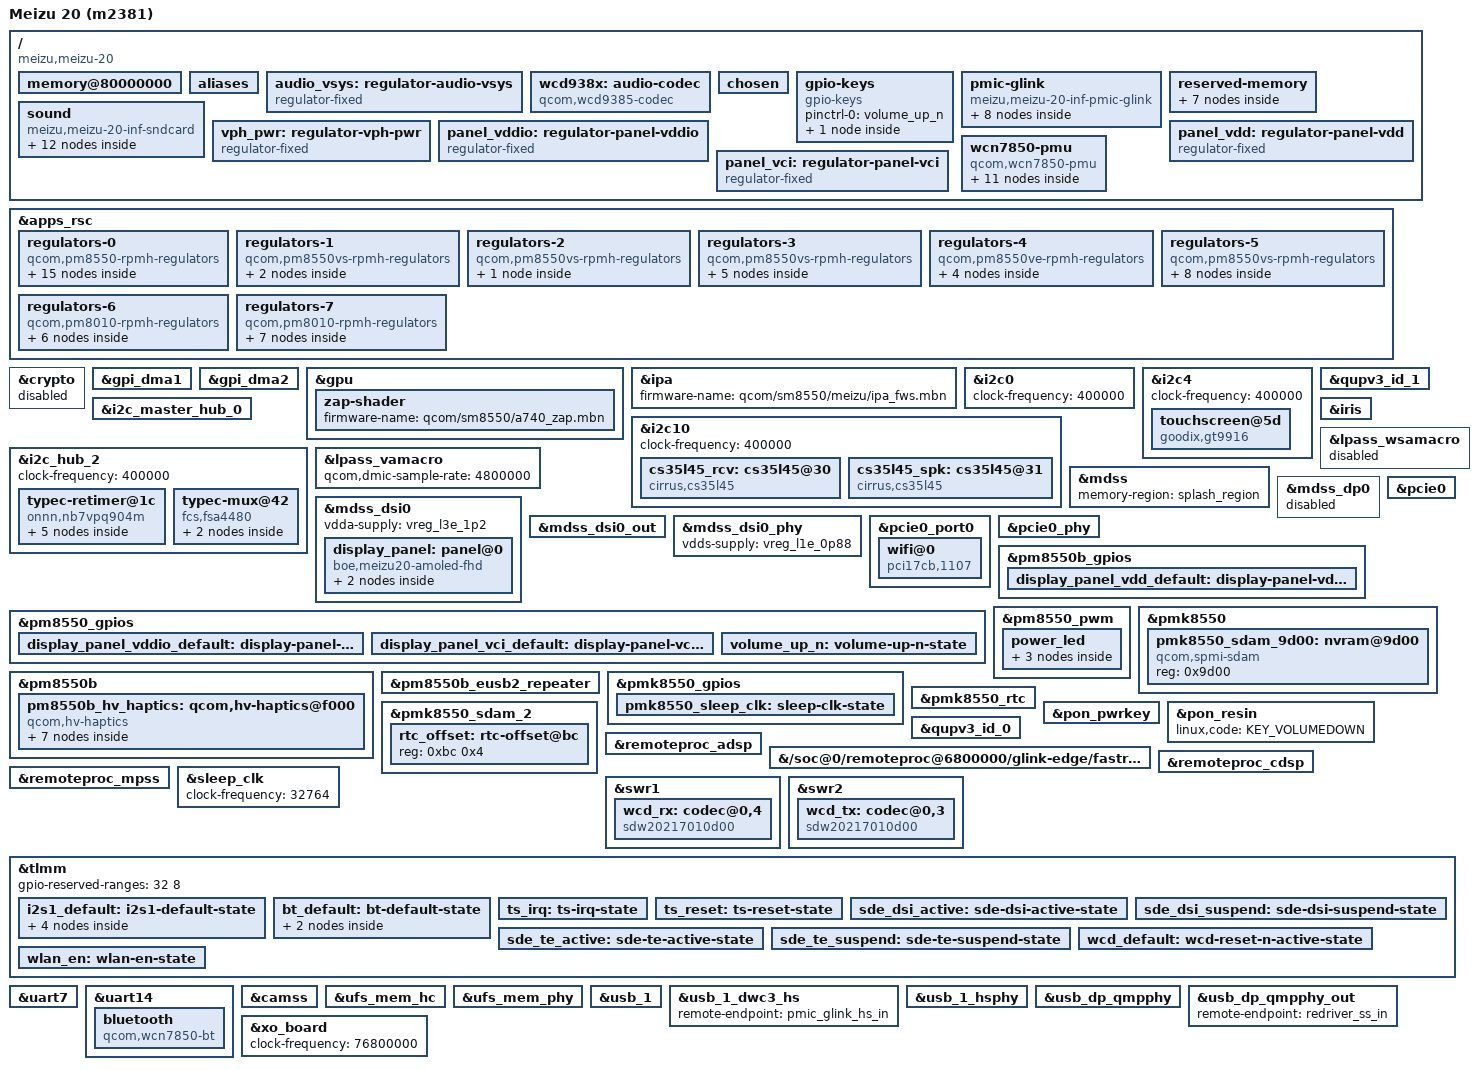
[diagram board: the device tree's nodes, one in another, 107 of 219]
// SPDX-License-Identifier: GPL-2.0-only
/*
 * Device Tree Source for Meizu 20 (m2381, SM8550/Kalama)
 * Copyright (c) 2026 Meizu Technologies
 *
 * factory-first 重建 v2（2026-10-03，DT 原厂化会话②）：
 * 本文件按 2026-10-04 用户拍板方针「本机原厂件为唯一事实源」整文件重建，
 * 取代 inf（Meizu 20 Infinity）派生旧版。逐节点出处与分类 =
 * meizu20-m1/dts/factory-first/LEDGER.md（台账，常驻维护——改此文件必须同步改台账）；
 * 原厂真值 = meizu20-m1/dts/factory-first/corpus/（vendor_boot base DTB + dtbo
 * entry9 + runtime FDT 三源，互验记录见同目录 README 与 reports/）。
 * 出处缩写：entry9 = dtbo entry9（本机生效 overlay）；RT = runtime FDT（ABL 后）。
 */
// SPDX-License-Identifier: BSD-3-Clause
/*
 * Copyright (c) 2025, Teguh Sobirin.
 */

/dts-v1/;
#include <dt-bindings/leds/common.h>
#include <dt-bindings/regulator/qcom,rpmh-regulator.h>
#include <dt-bindings/input/qcom,hv-haptics.h>
#include "sm8550.dtsi"
#include "pm8010.dtsi"
#include "pm8550.dtsi"
#include "pm8550b.dtsi"
#define PMK8550VE_SID 5
#include "pm8550ve.dtsi"
#include "pm8550vs.dtsi"
#include "pmk8550.dtsi"


/delete-node/ &rmtfs_mem;

/* sm8550.dtsi ships a placeholder memory node (reg size 0) and expects "the
 * bootloader to fill in the size".  We boot with a bare arm64 jump, so nobody
 * fills it - and with no /memory at all memblock is empty and paging_init()
 * panics with "Failed to allocate page table page".  The ranges below are
 * copied verbatim from this device's own bootloader-filled tree (stock
 * /sys/firmware/fdt, harvest 2026-09-21 = RT): the stock kernel booted with
 * exactly these values, so they are the platform's authoritative "OS memory".
 */
/delete-node/ &{/memory@a0000000};

/ {
	chassis-type = "handset";

	model = "Meizu 20 (m2381)";
	compatible = "meizu,meizu-20", "qcom,sm8550";

	/* RT: /memory 与本表同源（runtime FDT 即 boot 后地面真值）【D：裸跳需要】 */
	memory@80000000 {
		device_type = "memory";
		reg = <0x00 0x80000000 0x00 0xe00000>,
		      <0x00 0x811d0000 0x00 0x56e30000>,
		      <0x00 0xd8140000 0x00 0x20000>,
		      <0x00 0xd8800000 0x00 0x0>,
		      <0x00 0xe3bb0000 0x00 0x1c450000>,
		      <0x08 0x80000000 0x00 0x38700000>,
		      <0x08 0xc0000000 0x01 0x40000000>,
		      <0x0a 0x00 0x02 0x00>;
	};

	aliases {
		serial0 = &uart7;
		serial1 = &uart14;
	};

	/* CS35L45 VP 供电：stock 为无 GPIO 常开 fixed regulator（代表 VSYS 轨）
	 * 【D：主线 cs35l45 binding 需要 vdd-batt，stock 走不同框架】 */
	audio_vsys: regulator-audio-vsys {
		compatible = "regulator-fixed";
		regulator-name = "audio_vsys";
		regulator-always-on;
		regulator-boot-on;
	};

	wcd938x: audio-codec {
		compatible = "qcom,wcd9385-codec";
		/* reset-gpios=108 与 CS35L45 RCV 的 stock reset 同一网络（见 &i2c10 注），
		 * mainline 由本节点独占持有。
		 * 【A：RT wcd938x_reset_active/sleep = gpio108 ds16】*/
		pinctrl-names = "default";
		pinctrl-0 = <&wcd_default>;

		/* 【B：RT wcd938x-codec qcom,cdc-micbias1..4-mv 全部 0x708=1800mV；
		 * 旧 micbias2=2.7V 为 inf 派生偏差。音频 T3 假设（全 2.75V）与原厂
		 * 相反，随本行作废。2026-10-03 重建。】 */
		qcom,micbias1-microvolt = <1800000>;
		qcom,micbias2-microvolt = <1800000>;
		qcom,micbias3-microvolt = <1800000>;
		qcom,micbias4-microvolt = <1800000>;
		qcom,mbhc-buttons-vthreshold-microvolt = <75000 150000 237000 500000 500000 500000 500000 500000>;
		qcom,mbhc-headset-vthreshold-microvolt = <1700000>;
		qcom,mbhc-headphone-vthreshold-microvolt = <50000>;
		qcom,rx-device = <&wcd_rx>;
		qcom,tx-device = <&wcd_tx>;

		reset-gpios = <&tlmm 108 GPIO_ACTIVE_LOW>;

		vdd-buck-supply = <&vreg_l15b_1p8>;
		vdd-rxtx-supply = <&vreg_l15b_1p8>;
		vdd-io-supply = <&vreg_l15b_1p8>;
		vdd-mic-bias-supply = <&vreg_bob1>;

		#sound-dai-cells = <1>;
	};

	chosen {
		/*
		 * R23bi: no stdout-path on purpose.  The kernel console must become
		 * tty0/fbcon (fed by our glue's sysfb_primary_display fill + the
		 * earlycon=efifb that is already baked into CONFIG_CMDLINE); naming a
		 * serial here would make it the preferred console and the framebuffer
		 * console would stay disabled.
		 * 【D：UEFI 链控制台形态】
		 */
	};

	/* 【A：RT key_vol_up_default = pm8550 gpio6 input-enable pull-up】 */
	gpio-keys {
		compatible = "gpio-keys";

		pinctrl-0 = <&volume_up_n>;
		pinctrl-names = "default";

		key-volume-up {
			label = "Volume Up";
			debounce-interval = <15>;
			gpios = <&pm8550_gpios 6 GPIO_ACTIVE_LOW>;
			linux,code = <KEY_VOLUMEUP>;
			linux,can-disable;
			wakeup-source;
		};
	};

	pmic-glink {
		compatible = "meizu,meizu-20-inf-pmic-glink",
			     "qcom,sm8550-pmic-glink", "qcom,pmic-glink";
		#address-cells = <1>;
		#size-cells = <0>;
		orientation-gpios = <&tlmm 11 GPIO_ACTIVE_HIGH>;

		/*
		 * The board has no wireless charging hardware: the firmware
		 * never answers the wireless supply property requests, so
		 * skip those power supplies entirely.
		 * 【D：功耗战役产物，stock 树无此概念】
		 */
		qcom,no-wireless-charging;

		connector@0 {
			compatible = "usb-c-connector";
			reg = <0>;
			power-role = "dual";
			data-role = "dual";

			ports {
				#address-cells = <1>;
				#size-cells = <0>;

				port@0 {
					reg = <0>;

					pmic_glink_hs_in: endpoint {
						remote-endpoint = <&usb_1_dwc3_hs>;
					};
				};

				port@1 {
					reg = <1>;

					pmic_glink_ss_in: endpoint {
						remote-endpoint = <&redriver_ss_out>;
					};
				};

				port@2 {
					reg = <2>;

					pmic_glink_sbu: endpoint {
						remote-endpoint = <&fsa4480_sbu_mux>;
					};
				};
			};
		};
	};

	reserved-memory {
		/*
		 * Fixed firmware reservations below come from the SoC dtsi
		 * (sm8550.dtsi) plus these board additions, all cross-checked
		 * against the stock m2381 base DTB（2026-09-30 审计；本轮 corpus =
		 * 同一 base，复核入口 = factory-first/corpus/vboot_a.fdt0.dts）:
		 *  - chipinfo@81cf4000: stock-declared, no kernel consumer, kept
		 *    verbatim;
		 *  - hwfence-shbuf: stock is 0x2dd000, SoC dtsi only reserves
		 *    0x279000 - this node intentionally overrides it;
		 *  - llcc_lpi@ff800000: stock-declared, absent from the SoC dtsi;
		 *  - rmtfs@e7900000, splash@b8000000, ramoops@a5100000: board-
		 *    managed carveouts.
		 * 【待捕：全表逐项对账 = 板级分片（台账预留行）；现行值 9-30 审计过】
		 */
		ramoops@a5100000 {
			compatible = "ramoops";
			reg = <0 0xa5100000 0 0x200000>;
			console-size = <0x7d800>;
		};

		chipinfo_mem: chipinfo-region@81cf4000 {
			reg = <0 0x81cf4000 0 0x1000>;
			no-map;
		};

		hwfence_shbuf: hwfence-shbuf-region@e6440000 {
			reg = <0 0xe6440000 0 0x2dd000>;
			no-map;
		};

		llcc_lpi_mem: llcc_lpi_region@ff800000 {
			reg = <0 0xff800000 0 0x600000>;
			no-map;
		};

		rmtfs_mem: rmtfs-region@e7900000 {
			compatible = "qcom,rmtfs-mem";
			reg = <0x0 0xe7900000 0x0 0x280000>;
			no-map;

			qcom,client-id = <1>;
			qcom,vmid = <QCOM_SCM_VMID_MSS_MSA>;
		};

		splash_region: splash-region@b8000000 {
			reg = <0x0 0xb8000000 0x0 0x2b00000>;
			iommu-addresses = <&mdss 0x0 0xb8000000 0x0 0x2b00000>;
			no-map;
		};

		/*
		 * ADSP fastrpc remote heap: stock m2381 declares the same
		 * 12MB reusable pool (adsp_heap_region) and assigns the
		 * static-PD heap to {LPASS 0x16, ADSP_HEAP 0x25} -- same
		 * recipe as upstream sm8250/sm8750/kodiak.
		 */
		adsp_rpc_remote_heap_mem: adsp-rpc-remote-heap {
			compatible = "shared-dma-pool";
			alloc-ranges = <0x0 0x80000000 0x0 0x80000000>;
			reusable;
			alignment = <0x0 0x400000>;
			size = <0x0 0xc00000>;
		};
	};


	sound {
		compatible = "meizu,meizu-20-inf-sndcard",
			     "qcom,sm8550-sndcard", "qcom,sm8450-sndcard";
		pinctrl-0 = <&i2s1_default>;
		pinctrl-names = "default";

		model = "MEIZU20Inf";
		audio-routing = "IN1_HPHL", "HPHL_OUT",
				"IN2_HPHR", "HPHR_OUT",
				"AMIC1", "MIC BIAS1",
				"AMIC2", "MIC BIAS2",
				"AMIC3", "MIC BIAS3",
				"AMIC4", "MIC BIAS3",
				"AMIC5", "MIC BIAS4",
				"TX SWR_INPUT0", "ADC1_OUTPUT",
				"TX SWR_INPUT1", "ADC2_OUTPUT",
				"TX SWR_INPUT0", "ADC3_OUTPUT",
				"TX SWR_INPUT1", "ADC4_OUTPUT";
		wcd-playback-dai-link {
			link-name = "WCD Playback";
			cpu {
				sound-dai = <&q6apmbedai RX_CODEC_DMA_RX_0>;
			};
			codec {
				sound-dai = <&wcd938x 0>, <&swr1 0>, <&lpass_rxmacro 0>;
			};
			platform {
				sound-dai = <&q6apm>;
			};
		};

		wcd-capture-dai-link {
			link-name = "WCD Capture";
			cpu {
				sound-dai = <&q6apmbedai TX_CODEC_DMA_TX_3>;
			};
			codec {
				sound-dai = <&wcd938x 1>, <&swr2 0>, <&lpass_txmacro 0>;
			};
			platform {
				sound-dai = <&q6apm>;
			};
		};

		secondary-i2s-dai-link {
			link-name = "Secondary MI2S Playback";

			cpu {
				sound-dai = <&q6apmbedai SECONDARY_MI2S_RX>;
			};

			platform {
				sound-dai = <&q6apm>;
			};

			codec {
				sound-dai = <&cs35l45_rcv>, <&cs35l45_spk>;
			};
		};

		/*
		 * No displayport-0-dai-link: mdss_dp0 is disabled on m2381
		 * (2026-09-28 panel bring-up, see &mdss_dp0 above). A dai-link
		 * referencing a disabled codec leaves that ASoC component
		 * permanently absent, and the sm8550-sndcard machine driver
		 * silently defers forever = no sound card at all.
		 */
	};

	vph_pwr: regulator-vph-pwr {
		compatible = "regulator-fixed";
		regulator-name = "vph_pwr";
		regulator-min-microvolt = <3700000>;
		regulator-max-microvolt = <3700000>;

		regulator-always-on;
		regulator-boot-on;
	};

	/* ★显示供电三轨（factory-first 重建 2026-10-03，原厂出处见各行）：
	 * stock dsi-display-primary 的 vddio/vdd/vci 全部为 GPIO 门控轨
	 * （display_gpio_regulator@0/1/2，qti-regulator-fixed），不是 RPMH LDO。
	 * 门后物理轨电压由 PMIC 固件决定，节点内电压值 = stock 声明（文档用途）；
	 * r6/r7 活体实测：vddio 1.8V / vdd 1.2V / vci 3.0V——与 stock 声明不完全一致，
	 * 电压值不改物理轨，仅入台账备查。
	 * avdd（stock 供电表 4.6-6.0V，无人引用）：原厂不经 DT 管理该轨（PMIC 上电
	 * 常在），主线驱动 bulk 只取 vddio/vdd/vci ⇒ 不建节点（旧 avdd 5.5V@gpio11
	 * 死配线节点删除——gpio11 的原厂活角色是 vddi 使能）。
	 * 旧 inf 三轨（l12b/l11b/l13b）从 panel 节点摘除；LDO 本体保留在
	 * regulators-0（其他消费者在用）。 */

	/* vddio：RT display_gpio_regulator@0 "display_panel_vddi"，pm8550 gpio11，
	 * 1.8V，boot-on，enable-active-high，ramp 0xe9=233us，
	 * pinctrl display_panel_vddi_default（power-source 1, output-high） */
	panel_vddio: regulator-panel-vddio {
		compatible = "regulator-fixed";
		regulator-name = "display_panel_vddio";
		regulator-min-microvolt = <1800000>;
		regulator-max-microvolt = <1800000>;
		gpio = <&pm8550_gpios 11 GPIO_ACTIVE_HIGH>;
		enable-active-high;
		pinctrl-0 = <&display_panel_vddio_default>;
		pinctrl-names = "default";
		startup-delay-us = <233>;
		regulator-boot-on;
	};

	/* vdd：RT display_gpio_regulator@1 "display_panel_vddr"，pm8550b gpio5，
	 * 1.8V，boot-on，形态同 vddio */
	panel_vdd: regulator-panel-vdd {
		compatible = "regulator-fixed";
		regulator-name = "display_panel_vdd";
		regulator-min-microvolt = <1800000>;
		regulator-max-microvolt = <1800000>;
		gpio = <&pm8550b_gpios 5 GPIO_ACTIVE_HIGH>;
		enable-active-high;
		pinctrl-0 = <&display_panel_vdd_default>;
		pinctrl-names = "default";
		startup-delay-us = <233>;
		regulator-boot-on;
	};

	/* vci：RT display_gpio_regulator@2 "display_panel_vci"，pm8550 gpio1，
	 * 1.8V（声明），boot-on，pinctrl power-source 0（其余两轨为 1） */
	panel_vci: regulator-panel-vci {
		compatible = "regulator-fixed";
		regulator-name = "display_panel_vci";
		regulator-min-microvolt = <1800000>;
		regulator-max-microvolt = <1800000>;
		gpio = <&pm8550_gpios 1 GPIO_ACTIVE_HIGH>;
		enable-active-high;
		pinctrl-0 = <&display_panel_vci_default>;
		pinctrl-names = "default";
		startup-delay-us = <233>;
		regulator-boot-on;
	};

	/* 【A：RT wlan/bt enable pinctrl = gpio80/81；主线 wcn7850-pmu 形态】 */
	wcn7850-pmu {
		compatible = "qcom,wcn7850-pmu";

		pinctrl-names = "default";
		pinctrl-0 = <&wlan_en>, <&bt_default>, <&pmk8550_sleep_clk>;

		wlan-enable-gpios = <&tlmm 80 GPIO_ACTIVE_HIGH>;
        bt-enable-gpios = <&tlmm 81 GPIO_ACTIVE_HIGH>;

		vdd-supply = <&vreg_s5g_0p8>;
		vddio-supply = <&vreg_l15b_1p8>;
		vddaon-supply = <&vreg_s2g_0p8>;
		vdddig-supply = <&vreg_s4e_0p95>;
		vddrfa1p2-supply = <&vreg_s4g_1p3>;
		vddrfa1p8-supply = <&vreg_s6g_1p8>;

		regulators {
			vreg_pmu_rfa_cmn: ldo0 {
				regulator-name = "vreg_pmu_rfa_cmn";
			};

			vreg_pmu_aon_0p59: ldo1 {
				regulator-name = "vreg_pmu_aon_0p59";
			};

			vreg_pmu_wlcx_0p8: ldo2 {
				regulator-name = "vreg_pmu_wlcx_0p8";
			};

			vreg_pmu_wlmx_0p85: ldo3 {
				regulator-name = "vreg_pmu_wlmx_0p85";
			};

			vreg_pmu_btcmx_0p85: ldo4 {
				regulator-name = "vreg_pmu_btcmx_0p85";
			};

			vreg_pmu_rfa_0p8: ldo5 {
				regulator-name = "vreg_pmu_rfa_0p8";
			};

			vreg_pmu_rfa_1p2: ldo6 {
				regulator-name = "vreg_pmu_rfa_1p2";
			};

			vreg_pmu_rfa_1p8: ldo7 {
				regulator-name = "vreg_pmu_rfa_1p8";
			};

			vreg_pmu_pcie_0p9: ldo8 {
				regulator-name = "vreg_pmu_pcie_0p9";
			};

			vreg_pmu_pcie_1p8: ldo9 {
				regulator-name = "vreg_pmu_pcie_1p8";
			};
		};
	};
};

/* RPMH 轨位族：值族沿用 inf 派生（设备现役 20+ 天全子系统实跑验证），
 * **原厂对账 = 未做**（下游 RPMH 轨不在 DT，待板级分片按 RT regulator 节点
 * 逐轨对账，台账标「待捕」）。改轨前先看台账。 */
&apps_rsc {
	regulators-0 {
		compatible = "qcom,pm8550-rpmh-regulators";
		qcom,pmic-id = "b";

		vdd-bob1-supply = <&vph_pwr>;
		vdd-bob2-supply = <&vph_pwr>;
		vdd-l1-l4-l10-supply = <&vreg_s6g_1p8>;
		vdd-l2-l13-l14-supply = <&vreg_bob1>;
		vdd-l3-supply = <&vreg_s4g_1p3>;
		vdd-l5-l16-supply = <&vreg_bob1>;
		vdd-l6-l7-supply = <&vreg_bob1>;
		vdd-l8-l9-supply = <&vreg_bob1>;
		vdd-l11-supply = <&vreg_s4g_1p3>;
		vdd-l12-supply = <&vreg_s6g_1p8>;
		vdd-l15-supply = <&vreg_s6g_1p8>;
		vdd-l17-supply = <&vreg_bob2>;

		vreg_bob1: bob1 {
			regulator-name = "vreg_bob1";
			regulator-min-microvolt = <3296000>;
			regulator-max-microvolt = <3960000>;
			regulator-initial-mode = <RPMH_REGULATOR_MODE_HPM>;
		};

		vreg_bob2: bob2 {
			regulator-name = "vreg_bob2";
			regulator-min-microvolt = <2720000>;
			regulator-max-microvolt = <3960000>;
			regulator-initial-mode = <RPMH_REGULATOR_MODE_HPM>;
		};

		vreg_l2b_3p0: ldo2 {
			regulator-name = "vreg_l2b_3p0";
			regulator-min-microvolt = <3008000>;
			regulator-max-microvolt = <3008000>;
			regulator-initial-mode = <RPMH_REGULATOR_MODE_HPM>;
			regulator-allow-set-load;
			regulator-allowed-modes = <RPMH_REGULATOR_MODE_LPM
					   RPMH_REGULATOR_MODE_HPM>;
		};

		vreg_l5b_3p1: ldo5 {
			regulator-name = "vreg_l5b_3p1";
			regulator-min-microvolt = <3104000>;
			regulator-max-microvolt = <3104000>;
			regulator-initial-mode = <RPMH_REGULATOR_MODE_HPM>;
			regulator-allow-set-load;
			regulator-allowed-modes = <RPMH_REGULATOR_MODE_LPM
					   RPMH_REGULATOR_MODE_HPM>;
		};

		vreg_l6b_1p8: ldo6 {
			regulator-name = "vreg_l6b_1p8";
			regulator-min-microvolt = <1800000>;
			regulator-max-microvolt = <3008000>;
			regulator-initial-mode = <RPMH_REGULATOR_MODE_HPM>;
			regulator-allow-set-load;
			regulator-allowed-modes = <RPMH_REGULATOR_MODE_LPM
					   RPMH_REGULATOR_MODE_HPM>;
		};

		vreg_l7b_1p8: ldo7 {
			regulator-name = "vreg_l7b_1p8";
			regulator-min-microvolt = <1800000>;
			regulator-max-microvolt = <1800000>;
			regulator-initial-mode = <RPMH_REGULATOR_MODE_HPM>;
		};

		vreg_l8b_1p8: ldo8 {
			regulator-name = "vreg_l8b_1p8";
			regulator-min-microvolt = <1800000>;
			regulator-max-microvolt = <3008000>;
			regulator-initial-mode = <RPMH_REGULATOR_MODE_HPM>;
			regulator-allow-set-load;
			regulator-allowed-modes = <RPMH_REGULATOR_MODE_LPM
					   RPMH_REGULATOR_MODE_HPM>;
		};

		vreg_l9b_2p9: ldo9 {
			regulator-name = "vreg_l9b_2p9";
			regulator-min-microvolt = <2960000>;
			regulator-max-microvolt = <3008000>;
			regulator-initial-mode = <RPMH_REGULATOR_MODE_HPM>;
			regulator-allow-set-load;
			regulator-allowed-modes = <RPMH_REGULATOR_MODE_LPM
					   RPMH_REGULATOR_MODE_HPM>;
		};

		vreg_l11b_1p1: ldo11 {
			regulator-name = "vreg_l11b_1p1";
			regulator-min-microvolt = <1100000>;
			regulator-max-microvolt = <1504000>;
			regulator-initial-mode = <RPMH_REGULATOR_MODE_HPM>;
			regulator-allow-set-load;
			regulator-allowed-modes = <RPMH_REGULATOR_MODE_LPM
					   RPMH_REGULATOR_MODE_HPM>;
		};

		vreg_l12b_1p8: ldo12 {
			regulator-name = "vreg_l12b_1p8";
			regulator-min-microvolt = <1800000>;
			regulator-max-microvolt = <1800000>;
			regulator-initial-mode = <RPMH_REGULATOR_MODE_HPM>;
			regulator-allow-set-load;
			regulator-allowed-modes = <RPMH_REGULATOR_MODE_LPM
					   RPMH_REGULATOR_MODE_HPM>;
		};

		vreg_l13b_3p0: ldo13 {
			regulator-name = "vreg_l13b_3p0";
			regulator-min-microvolt = <3000000>;
			regulator-max-microvolt = <3000000>;
			regulator-initial-mode = <RPMH_REGULATOR_MODE_HPM>;
		};

		vreg_l14b_3p2: ldo14 {
			regulator-name = "vreg_l14b_3p2";
			regulator-min-microvolt = <3200000>;
			regulator-max-microvolt = <3200000>;
			regulator-initial-mode = <RPMH_REGULATOR_MODE_HPM>;
		};

		vreg_l15b_1p8: ldo15 {
			regulator-name = "vreg_l15b_1p8";
			regulator-min-microvolt = <1800000>;
			regulator-max-microvolt = <1800000>;
			regulator-initial-mode = <RPMH_REGULATOR_MODE_HPM>;
			regulator-allow-set-load;
			regulator-allowed-modes = <RPMH_REGULATOR_MODE_LPM
					   RPMH_REGULATOR_MODE_HPM>;
		};

		vreg_l16b_2p8: ldo16 {
			regulator-name = "vreg_l16b_2p8";
			regulator-min-microvolt = <2800000>;
			regulator-max-microvolt = <2800000>;
			regulator-initial-mode = <RPMH_REGULATOR_MODE_HPM>;
		};

		vreg_l17b_2p5: ldo17 {
			regulator-name = "vreg_l17b_2p5";
			regulator-min-microvolt = <2504000>;
			regulator-max-microvolt = <2504000>;
			regulator-initial-mode = <RPMH_REGULATOR_MODE_HPM>;
		};
	};

	regulators-1 {
		compatible = "qcom,pm8550vs-rpmh-regulators";
		qcom,pmic-id = "c";

		vdd-l1-supply = <&vreg_s4g_1p3>;
		vdd-l2-supply = <&vreg_s4e_0p95>;
		vdd-l3-supply = <&vreg_s4e_0p95>;

		vreg_l1c_1p2: ldo1 {
			regulator-name = "vreg_l1c_1p2";
			regulator-min-microvolt = <1200000>;
			regulator-max-microvolt = <1200000>;
			regulator-initial-mode = <RPMH_REGULATOR_MODE_HPM>;
			regulator-allow-set-load;
			regulator-allowed-modes = <RPMH_REGULATOR_MODE_LPM
					   RPMH_REGULATOR_MODE_HPM>;
		};

		vreg_l3c_0p9: ldo3 {
			regulator-name = "vreg_l3c_0p9";
			regulator-min-microvolt = <880000>;
			regulator-max-microvolt = <912000>;
			regulator-initial-mode = <RPMH_REGULATOR_MODE_HPM>;
			regulator-allow-set-load;
			regulator-allowed-modes = <RPMH_REGULATOR_MODE_LPM
					   RPMH_REGULATOR_MODE_HPM>;
		};
	};

	regulators-2 {
		compatible = "qcom,pm8550vs-rpmh-regulators";
		qcom,pmic-id = "d";

		vdd-l1-supply = <&vreg_s4e_0p95>;
		vdd-l2-supply = <&vreg_s4e_0p95>;
		vdd-l3-supply = <&vreg_s4e_0p95>;

		vreg_l1d_0p88: ldo1 {
			regulator-name = "vreg_l1d_0p88";
			regulator-min-microvolt = <880000>;
			regulator-max-microvolt = <920000>;
			regulator-initial-mode = <RPMH_REGULATOR_MODE_HPM>;
			regulator-allow-set-load;
			regulator-allowed-modes = <RPMH_REGULATOR_MODE_LPM
					   RPMH_REGULATOR_MODE_HPM>;
		};
	};

	regulators-3 {
		compatible = "qcom,pm8550vs-rpmh-regulators";
		qcom,pmic-id = "e";

		vdd-l1-supply = <&vreg_s4e_0p95>;
		vdd-l2-supply = <&vreg_s4e_0p95>;
		vdd-l3-supply = <&vreg_s4g_1p3>;
		vdd-s4-supply = <&vph_pwr>;
		vdd-s5-supply = <&vph_pwr>;

		vreg_s4e_0p95: smps4 {
			regulator-name = "vreg_s4e_0p95";
			regulator-min-microvolt = <904000>;
			regulator-max-microvolt = <984000>;
			regulator-initial-mode = <RPMH_REGULATOR_MODE_HPM>;
		};

		vreg_s5e_1p08: smps5 {
			regulator-name = "vreg_s5e_1p08";
			regulator-min-microvolt = <1010000>;
			regulator-max-microvolt = <1120000>;
			regulator-initial-mode = <RPMH_REGULATOR_MODE_HPM>;
		};

		vreg_l1e_0p88: ldo1 {
			regulator-name = "vreg_l1e_0p88";
			regulator-min-microvolt = <880000>;
			regulator-max-microvolt = <912000>;
			regulator-initial-mode = <RPMH_REGULATOR_MODE_HPM>;
			regulator-allow-set-load;
			regulator-allowed-modes = <RPMH_REGULATOR_MODE_LPM
					   RPMH_REGULATOR_MODE_HPM>;
		};

		vreg_l2e_0p9: ldo2 {
			regulator-name = "vreg_l2e_0p9";
			regulator-min-microvolt = <870000>;
			regulator-max-microvolt = <970000>;
			regulator-initial-mode = <RPMH_REGULATOR_MODE_HPM>;
			regulator-allow-set-load;
			regulator-allowed-modes = <RPMH_REGULATOR_MODE_LPM
					   RPMH_REGULATOR_MODE_HPM>;
		};

		vreg_l3e_1p2: ldo3 {
			regulator-name = "vreg_l3e_1p2";
			regulator-min-microvolt = <1200000>;
			regulator-max-microvolt = <1200000>;
			regulator-initial-mode = <RPMH_REGULATOR_MODE_HPM>;
		};
	};

	regulators-4 {
		compatible = "qcom,pm8550ve-rpmh-regulators";
		qcom,pmic-id = "f";

		vdd-l1-supply = <&vreg_s4e_0p95>;
		vdd-l2-supply = <&vreg_s4e_0p95>;
		vdd-l3-supply = <&vreg_s4e_0p95>;
		vdd-s4-supply = <&vph_pwr>;

		vreg_s4f_0p5: smps4 {
			regulator-name = "vreg_s4f_0p5";
			regulator-min-microvolt = <300000>;
			regulator-max-microvolt = <700000>;
			regulator-initial-mode = <RPMH_REGULATOR_MODE_HPM>;
		};

		vreg_l1f_0p9: ldo1 {
			regulator-name = "vreg_l1f_0p9";
			regulator-min-microvolt = <880000>;
			regulator-max-microvolt = <912000>;
			regulator-initial-mode = <RPMH_REGULATOR_MODE_HPM>;
			regulator-allow-set-load;
			regulator-allowed-modes = <RPMH_REGULATOR_MODE_LPM
					   RPMH_REGULATOR_MODE_HPM>;
		};

		vreg_l2f_0p88: ldo2 {
			regulator-name = "vreg_l2f_0p88";
			regulator-min-microvolt = <880000>;
			regulator-max-microvolt = <912000>;
			regulator-initial-mode = <RPMH_REGULATOR_MODE_HPM>;
			regulator-allow-set-load;
			regulator-allowed-modes = <RPMH_REGULATOR_MODE_LPM
					   RPMH_REGULATOR_MODE_HPM>;
		};

		vreg_l3f_0p88: ldo3 {
			regulator-name = "vreg_l3f_0p88";
			regulator-min-microvolt = <880000>;
			regulator-max-microvolt = <912000>;
			regulator-initial-mode = <RPMH_REGULATOR_MODE_HPM>;
			regulator-allow-set-load;
			regulator-allowed-modes = <RPMH_REGULATOR_MODE_LPM
					   RPMH_REGULATOR_MODE_HPM>;
		};
	};

	regulators-5 {
		compatible = "qcom,pm8550vs-rpmh-regulators";
		qcom,pmic-id = "g";

		vdd-l1-supply = <&vreg_s4g_1p3>;
		vdd-l2-supply = <&vreg_s4g_1p3>;
		vdd-l3-supply = <&vreg_s4g_1p3>;
		vdd-s1-supply = <&vph_pwr>;
		vdd-s2-supply = <&vph_pwr>;
		vdd-s3-supply = <&vph_pwr>;
		vdd-s4-supply = <&vph_pwr>;
		vdd-s5-supply = <&vph_pwr>;
		vdd-s6-supply = <&vph_pwr>;

		vreg_s1g_1p2: smps1 {
			regulator-name = "vreg_s1g_1p2";
			regulator-min-microvolt = <1200000>;
			regulator-max-microvolt = <1300000>;
			regulator-initial-mode = <RPMH_REGULATOR_MODE_HPM>;
		};

		vreg_s2g_0p8: smps2 {
			regulator-name = "vreg_s2g_0p8";
			regulator-min-microvolt = <500000>;
			regulator-max-microvolt = <1036000>;
			regulator-initial-mode = <RPMH_REGULATOR_MODE_HPM>;
		};

		vreg_s3g_0p7: smps3 {
			regulator-name = "vreg_s3g_0p7";
			regulator-min-microvolt = <300000>;
			regulator-max-microvolt = <1004000>;
			regulator-initial-mode = <RPMH_REGULATOR_MODE_HPM>;
		};

		vreg_s4g_1p3: smps4 {
			regulator-name = "vreg_s4g_1p3";
			regulator-min-microvolt = <1200000>;
			regulator-max-microvolt = <1352000>;
			regulator-initial-mode = <RPMH_REGULATOR_MODE_HPM>;
		};

		vreg_s5g_0p8: smps5 {
			regulator-name = "vreg_s5g_0p8";
			regulator-min-microvolt = <500000>;
			regulator-max-microvolt = <1004000>;
			regulator-initial-mode = <RPMH_REGULATOR_MODE_HPM>;
		};

		vreg_s6g_1p8: smps6 {
			regulator-name = "vreg_s6g_1p8";
			regulator-min-microvolt = <1800000>;
			regulator-max-microvolt = <2000000>;
			regulator-initial-mode = <RPMH_REGULATOR_MODE_HPM>;
		};

		vreg_l1g_1p2: ldo1 {
			regulator-name = "vreg_l1g_1p2";
			regulator-min-microvolt = <1200000>;
			regulator-max-microvolt = <1200000>;
			regulator-initial-mode = <RPMH_REGULATOR_MODE_HPM>;
			regulator-allow-set-load;
			regulator-allowed-modes = <RPMH_REGULATOR_MODE_LPM
					   RPMH_REGULATOR_MODE_HPM>;
		};

		vreg_l3g_1p2: ldo3 {
			regulator-name = "vreg_l3g_1p2";
			regulator-min-microvolt = <1200000>;
			regulator-max-microvolt = <1200000>;
			regulator-initial-mode = <RPMH_REGULATOR_MODE_HPM>;
		};
	};

	regulators-6 {
		compatible = "qcom,pm8010-rpmh-regulators";
		qcom,pmic-id = "m";

		vdd-l1-l2-supply = <&vreg_s4g_1p3>;
		vdd-l3-l4-supply = <&vreg_bob2>;
		vdd-l5-supply = <&vreg_s6g_1p8>;
		vdd-l6-supply = <&vreg_bob2>;
		vdd-l7-supply = <&vreg_bob2>;

		vreg_l1m_1p056: ldo1 {
			regulator-name = "vreg_l1m_1p056";
			regulator-min-microvolt = <1056000>;
			regulator-max-microvolt = <1056000>;
			regulator-initial-mode = <RPMH_REGULATOR_MODE_HPM>;
		};

		vreg_l2m_1p056: ldo2 {
			regulator-name = "vreg_l2m_1p056";
			regulator-min-microvolt = <1056000>;
			regulator-max-microvolt = <1056000>;
			regulator-initial-mode = <RPMH_REGULATOR_MODE_HPM>;
		};

		vreg_l3m_2p8: ldo3 {
			regulator-name = "vreg_l3m_2p8";
			regulator-min-microvolt = <2800000>;
			regulator-max-microvolt = <2800000>;
			regulator-initial-mode = <RPMH_REGULATOR_MODE_HPM>;
		};

		vreg_l4m_2p8: ldo4 {
			regulator-name = "vreg_l4m_2p8";
			regulator-min-microvolt = <2800000>;
			regulator-max-microvolt = <2800000>;
			regulator-initial-mode = <RPMH_REGULATOR_MODE_HPM>;
		};

		vreg_l5m_1p8: ldo5 {
			regulator-name = "vreg_l5m_1p8";
			regulator-min-microvolt = <1800000>;
			regulator-max-microvolt = <1800000>;
			regulator-initial-mode = <RPMH_REGULATOR_MODE_HPM>;
		};

		vreg_l7m_2p904: ldo7 {
			regulator-name = "vreg_l7m_2p904";
			regulator-min-microvolt = <2904000>;
			regulator-max-microvolt = <3500000>;
			regulator-initial-mode = <RPMH_REGULATOR_MODE_HPM>;
		};
	};

	regulators-7 {
		compatible = "qcom,pm8010-rpmh-regulators";
		qcom,pmic-id = "n";

		vdd-l1-l2-supply = <&vreg_s4g_1p3>;
		vdd-l3-l4-supply = <&vreg_bob2>;
		vdd-l5-supply = <&vreg_s6g_1p8>;
		vdd-l6-supply = <&vreg_bob1>;
		vdd-l7-supply = <&vreg_bob1>;

		vreg_l1n_1p104: ldo1 {
			regulator-name = "vreg_l1n_1p104";
			regulator-min-microvolt = <1104000>;
			regulator-max-microvolt = <1104000>;
			regulator-initial-mode = <RPMH_REGULATOR_MODE_HPM>;
		};

		vreg_l2n_1p056: ldo2 {
			regulator-name = "vreg_l2n_1p056";
			regulator-min-microvolt = <1056000>;
			regulator-max-microvolt = <1104000>;
			regulator-initial-mode = <RPMH_REGULATOR_MODE_HPM>;
		};

		vreg_l3n_2p8: ldo3 {
			regulator-name = "vreg_l3n_2p8";
			regulator-min-microvolt = <2800000>;
			regulator-max-microvolt = <2800000>;
			regulator-initial-mode = <RPMH_REGULATOR_MODE_HPM>;
		};

		vreg_l4n_2p8: ldo4 {
			regulator-name = "vreg_l4n_2p8";
			regulator-min-microvolt = <2800000>;
			regulator-max-microvolt = <2800000>;
			regulator-initial-mode = <RPMH_REGULATOR_MODE_HPM>;
		};

		vreg_l5n_1p8: ldo5 {
			regulator-name = "vreg_l5n_1p8";
			regulator-min-microvolt = <1800000>;
			regulator-max-microvolt = <1800000>;
			regulator-initial-mode = <RPMH_REGULATOR_MODE_HPM>;
			regulator-always-on;
		};

		vreg_l6n_2p8: ldo6 {
			regulator-name = "vreg_l6n_2p8";
			regulator-min-microvolt = <2800000>;
			regulator-max-microvolt = <2800000>;
			regulator-initial-mode = <RPMH_REGULATOR_MODE_HPM>;
			regulator-always-on;
		};

		vreg_l7n_2p96: ldo7 {
			regulator-name = "vreg_l7n_2p96";
			regulator-min-microvolt = <2800000>;
			regulator-max-microvolt = <2960000>;
			regulator-initial-mode = <RPMH_REGULATOR_MODE_HPM>;
		};
	};
};

&crypto {
	/* QCE cannot be used safely while it is shared with the secure world. */
	status = "disabled";
};

&gpi_dma1 {
	status = "okay";
};

&gpi_dma2 {
	status = "okay";
};

&gpu {
	status = "okay";

	zap-shader {
		firmware-name = "qcom/sm8550/a740_zap.mbn";
	};
};

&ipa {
	firmware-name = "qcom/sm8550/meizu/ipa_fws.mbn";
	status = "okay";
};

&i2c0 {
	clock-frequency = <400000>;
	status = "okay";
};

/* 【A：entry9 qcom,i2c-touch-active="goodix,gt9916" + goodix-berlin@5d，
 * reset 0x18=24 / irq 0x19=25、1080×2400 全同】 */
&i2c4 {
	clock-frequency = <400000>;
	status = "okay";

	touchscreen@5d {
		compatible = "goodix,gt9916";
		reg = <0x5d>;

		pinctrl-0 = <&ts_irq>, <&ts_reset>;
		pinctrl-names = "default";

		interrupt-parent = <&tlmm>;
		interrupts = <25 IRQ_TYPE_EDGE_FALLING>;
		reset-gpios = <&tlmm 24 GPIO_ACTIVE_LOW>;

		/* 【B 待捕：stock avdd = humu L9B ~2.96V（我方 l14b 3.2V，触控在用）】 */
		avdd-supply = <&vreg_l14b_3p2>;
		vddio-supply = <&vreg_l12b_1p8>;

		touchscreen-size-x = <1080>;
		touchscreen-size-y = <2400>;
	};
};

&i2c_master_hub_0 {
	status = "okay";
};

/* m2381 扬声器/听筒 = Cirrus CS35L45 ×2（stock dtbo + 运行时 FDT + vendor wmfw 三路实锤；
 * 旧 tfa9875@34/35 为 silime inf dts 虚构，随 &i2c8 使能块一并删除——880000 总线无真实器件）。
 * 【A：RT cs35l45@30=dsp-part-name cs35l45-rcv / @31=cs35l45-spk】 */
&qupv3_id_1 {
	status = "okay";
};

&i2c10 {
	clock-frequency = <400000>;
	status = "okay";

	cs35l45_rcv: cs35l45@30 {
		compatible = "cirrus,cs35l45";
		reg = <0x30>;
		#sound-dai-cells = <0>;
		sound-name-prefix = "RCV";

		/*
		 * stock reset-gpios = <&tlmm 108>（RT cs35l45-rcv 节点），与 wcd938x
		 * reset 同一网络（stock 两侧都写在各自节点，靠 Android 端 wcd 平台节点
		 * disabled 规避双持）。mainline 只让 wcd938x 持有该线：wcd probe 先行
		 * 复位/释放，RCV 随之出复位，故省略。
		 */
		vdd-a-supply = <&vreg_l15b_1p8>;
		vdd-batt-supply = <&audio_vsys>;
	};

	cs35l45_spk: cs35l45@31 {
		compatible = "cirrus,cs35l45";
		reg = <0x31>;
		#sound-dai-cells = <0>;
		sound-name-prefix = "SPK";

		vdd-a-supply = <&vreg_l15b_1p8>;
		vdd-batt-supply = <&audio_vsys>;
	};
};

&i2c_hub_2 {
	clock-frequency = <400000>;
	status = "okay";

	/**
    fsa4480@42
    rtc6226@64
    onnn redriver@1c
    **/
    typec-retimer@1c {
		compatible = "onnn,nb7vpq904m";
		reg = <0x1c>;

		vcc-supply = <&vreg_l15b_1p8>;

		retimer-switch;
		orientation-switch;

		ports {
			#address-cells = <1>;
			#size-cells = <0>;

			port@0 {
				reg = <0>;

				redriver_ss_out: endpoint {
					remote-endpoint = <&pmic_glink_ss_in>;
				};
			};

			port@1 {
				reg = <1>;

				redriver_ss_in: endpoint {
					data-lanes = <3 2 1 0>;
					remote-endpoint = <&usb_dp_qmpphy_out>;
				};
			};
		};
	};

    typec-mux@42 {
		compatible = "fcs,fsa4480";
		reg = <0x42>;

		vcc-supply = <&vreg_bob1>;

		mode-switch;
		orientation-switch;

		port {
			fsa4480_sbu_mux: endpoint {
				remote-endpoint = <&pmic_glink_sbu>;
			};
		};
	};
};

&iris {
	status = "okay";
};

&lpass_vamacro {
	qcom,dmic-sample-rate = <4800000>;
};

&lpass_wsamacro {
	status = "disabled";
};

&mdss {
	memory-region = <&splash_region>;
	status = "okay";
};

&mdss_dp0 {
	/* m2381: DP 组件 deferred 拖死 DRM 组件等待 ⇒ DSI/panel 永不 probe;
	 * 本机无 DP 用例,禁用(2026-09-28 面板 bring-up)。stock 有完整 DP 树
	 * （entry 间差异项），复用等 dp0 冲突面调研后再议。 */
	status = "disabled";
};

/* ★显示分片①（factory-first 重建 2026-10-03）：
 * - reset = TLMM **133**（原厂双证：entry9 qcom,platform-reset-gpio=0x85 + RT 同值；
 *   pinctrl sde_dsi_active/suspend 同脚。旧 205 为 inf 派生错值；210 系 UFS 复位脚，
 *   硬定律#9「Mu 写 GPIO210 即死」= 写 UFS 复位线，历史自洽）。
 * - 供电三轨 = GPIO 门控轨（见文件头 panel_vddio/vdd/vci），旧 LDO 三轨摘除。
 * - TE/pinctrl/时序面 A 类不变：te-source mdp_vsync_p、sde_te gpio86；驱动
 *   120Hz 模式 porch 50/16/50+20/4/12 与 entry9 timing@0 同（htotal 1196 自洽）。
 * - 驱动时序/序列与 stock 120Hz 档逐字节同（FINDINGS 三源对账）；bitclk 1094 =
 *   entry9 panel-clockrate 四档全值。 */
&mdss_dsi0 {
	vdda-supply = <&vreg_l3e_1p2>;
	status = "okay";

	display_panel: panel@0 {
		/* m2381: BOE AMOLED FHD+ 1080x2400 cmd+DSC, PanelID B5011A05
		 * （DDIC = Novatek 族，DSIDSCProfileID=0xB=主机不发 PPS 特类）。
		 * 驱动 = 自写 panel-boe-meizu20.c（TODO(m2381-panel)：mainline 尚无此面板），
		 * 节点保持主线形态，输入按原厂纠正（本注释块即出处）。
		 * 真值表 = factory-first/reports/PANEL-GROUND-TRUTH.md。 */
		compatible = "boe,meizu20-amoled-fhd";
		reg = <0>;

		pinctrl-0 = <&sde_dsi_active>, <&sde_te_active>;
		pinctrl-1 = <&sde_dsi_suspend>, <&sde_te_suspend>;
		pinctrl-names = "default", "sleep";

		vddio-supply = <&panel_vddio>;
		vdd-supply = <&panel_vdd>;
		vci-supply = <&panel_vci>;

		reset-gpios = <&tlmm 133 GPIO_ACTIVE_LOW>;

		port {
			panel0_in: endpoint {
				remote-endpoint = <&mdss_dsi0_out>;
			};
		};
	};
};

&mdss_dsi0_out {
	remote-endpoint = <&panel0_in>;
	data-lanes = <0 1 2 3>;
	/* 【A：entry9 qcom,platform-te-gpio = tlmm 86；Android 主外部 TE 输入】 */
	qcom,te-source = "mdp_vsync_p";
};

&mdss_dsi0_phy {
	vdds-supply = <&vreg_l1e_0p88>;
	status = "okay";
};

&pcie0 {
	wake-gpios = <&tlmm 96 GPIO_ACTIVE_HIGH>;
	perst-gpios = <&tlmm 94 GPIO_ACTIVE_LOW>;

	pinctrl-0 = <&pcie0_default_state>;
	pinctrl-names = "default";

	status = "okay";
};

&pcie0_port0 {
	wifi@0 {
		compatible = "pci17cb,1107";
		reg = <0x10000 0x0 0x0 0x0 0x0>;
		qcom,soc-serial-mac-address;

		vddrfacmn-supply = <&vreg_pmu_rfa_cmn>;
		vddaon-supply = <&vreg_pmu_aon_0p59>;
		vddwlcx-supply = <&vreg_pmu_wlcx_0p8>;
		vddwlmx-supply = <&vreg_pmu_wlmx_0p85>;
		vddrfa0p8-supply = <&vreg_pmu_rfa_0p8>;
		vddrfa1p2-supply = <&vreg_pmu_rfa_1p2>;
		vddrfa1p8-supply = <&vreg_pmu_rfa_1p8>;
		vddpcie0p9-supply = <&vreg_pmu_pcie_0p9>;
		vddpcie1p8-supply = <&vreg_pmu_pcie_1p8>;
	};
};

&pcie0_phy {
	vdda-phy-supply = <&vreg_l1e_0p88>;
	vdda-pll-supply = <&vreg_l3e_1p2>;

	status = "okay";
};

/* 【A：RT pm8550_gpios（0x5bd）display_panel_vddi_default = gpio11 output-high
 *  power-source 1；display_panel_vci_default = gpio1 output-high power-source 0；
 *  volume key = gpio6 pull-up input】 */
&pm8550_gpios {
	display_panel_vddio_default: display-panel-vddio-default-state {
		pins = "gpio11";
		function = "normal";
		power-source = <1>;
		bias-disable;
		output-high;
	};

	display_panel_vci_default: display-panel-vci-default-state {
		pins = "gpio1";
		function = "normal";
		power-source = <0>;
		bias-disable;
		output-high;
	};

		volume_up_n: volume-up-n-state {
		pins = "gpio6";
		function = "normal";
		power-source = <1>;
		bias-pull-up;
		input-enable;
	};
};

/* 【A：RT pm8550b_gpios（0x5ef）display_panel_vddr_default = gpio5 output-high
 *  power-source 1】 */
&pm8550b_gpios {
	display_panel_vdd_default: display-panel-vdd-default-state {
		pins = "gpio5";
		function = "normal";
		power-source = <1>;
		bias-disable;
		output-high;
	};
};

&pm8550_pwm {
	status = "okay";

	power_led {
		color = <LED_COLOR_ID_RGB>;
		label = "power-led";

		#address-cells = <1>;
		#size-cells = <0>;

		red@1 {
			reg = <1>;
			color = <LED_COLOR_ID_RED>;
		};

		green@2 {
			reg = <2>;
			color = <LED_COLOR_ID_GREEN>;
		};

		blue@3 {
			reg = <3>;
			color = <LED_COLOR_ID_BLUE>;
		};
	};
};

&pmk8550 {
	pmk8550_sdam_9d00: nvram@9d00 {
		compatible = "qcom,spmi-sdam";
		reg = <0x9d00>;
	};
};

&pm8550b {
	pm8550b_hv_haptics: qcom,hv-haptics@f000 {
		compatible = "qcom,hv-haptics";

		reg = <0xf000>, <0xf100>, <0xf200>;

		interrupts = <0x07 0xf0 0x01 IRQ_TYPE_EDGE_RISING>;
		interrupt-names = "fifo-empty";

		/*
		 * Android:
		 * qcom,vmax-mv-factory = <0x640>;
		 * qcom,vmax-mv-cali    = <0x640>;
		 * qcom,vmax-mv         = <0x2198>;
		 *
		 * 0x640  = 1600 mV
		 * 0x2198 = 8600 mV
		 * 【待捕：entry9 侧 haptics vmax 全族对账 = 震动零设备首查】
		 */
		qcom,vmax-mv-factory = <1600>;
		qcom,vmax-mv-cali = <1600>;
		qcom,vmax-mv = <8600>;

		qcom,brake-mode = <BRAKE_CLOSE_LOOP>;
		qcom,brake-pattern = /bits/ 8 <0xff 0x3f 0x1f>;
		qcom,lra-period-us = <5880>;
		qcom,drv-sig-shape = <WF_SINE>;
		qcom,brake-sig-shape = <WF_SINE>;

		nvmem-names = "hap_cfg_sdam";
		nvmem = <&pmk8550_sdam_9d00>;

		status = "okay";

		hap_swr_slave_reg: qcom,hap-swr-slave-reg {
			regulator-name = "hap-swr-slave-reg";
		};

		effect_0 {
			qcom,effect-id = <0x00>;

			qcom,wf-vmax-mv = <5000>;

			qcom,wf-pattern-data =
				<0x01f 0x00 0x00
				 0x03f 0x00 0x00
				 0x05f 0x00 0x00
				 0x07f 0x00 0x00
				 0x17f 0x00 0x00
				 0x15f 0x00 0x00
				 0x13f 0x00 0x00
				 0x11f 0x00 0x00>;

			qcom,wf-pattern-period-us = <5880>;

			qcom,wf-brake-pattern =
				/bits/ 8 <0x00 0x00 0x00>;

			qcom,wf-pattern-preload;
			qcom,wf-auto-res-disable;
		};

		effect_1 {
			qcom,effect-id = <0x01>;

			qcom,wf-vmax-mv = <5000>;

			qcom,wf-pattern-data =
				<0x01f 0x00 0x00
				 0x03f 0x00 0x00
				 0x05f 0x00 0x00
				 0x07f 0x00 0x00
				 0x17f 0x00 0x00
				 0x15f 0x00 0x00
				 0x13f 0x00 0x00
				 0x11f 0x00 0x00>;

			qcom,wf-pattern-period-us = <5880>;

			qcom,wf-brake-pattern =
				/bits/ 8 <0x00 0x00 0x00>;

			qcom,wf-auto-res-disable;
		};

		effect_2 {
			qcom,effect-id = <0x02>;

			qcom,wf-vmax-mv = <5000>;

			qcom,wf-pattern-data =
				<0x01f 0x00 0x00
				 0x03f 0x00 0x00
				 0x05f 0x00 0x00
				 0x07f 0x00 0x00
				 0x17f 0x00 0x00
				 0x15f 0x00 0x00
				 0x13f 0x00 0x00
				 0x11f 0x00 0x00>;

			qcom,wf-pattern-period-us = <5880>;

			qcom,wf-brake-pattern =
				/bits/ 8 <0x00 0x00 0x00>;

			qcom,wf-auto-res-disable;
		};

		effect_3 {
			qcom,effect-id = <0x03>;

			qcom,wf-vmax-mv = <5000>;

			qcom,wf-pattern-data =
				<0x01f 0x00 0x00
				 0x03f 0x00 0x00
				 0x05f 0x00 0x00
				 0x07f 0x00 0x00
				 0x17f 0x00 0x00
				 0x15f 0x00 0x00
				 0x13f 0x00 0x00
				 0x11f 0x00 0x00>;

			qcom,wf-pattern-period-us = <5880>;

			qcom,wf-brake-pattern =
				/bits/ 8 <0x00 0x00 0x00>;

			qcom,wf-auto-res-disable;
		};

		effect_4 {
			qcom,effect-id = <0x04>;

			qcom,wf-vmax-mv = <5000>;

			qcom,wf-pattern-data =
				<0x01f 0x00 0x00
				 0x03f 0x00 0x00
				 0x05f 0x00 0x00
				 0x07f 0x00 0x00
				 0x17f 0x00 0x00
				 0x15f 0x00 0x00
				 0x13f 0x00 0x00
				 0x11f 0x00 0x00>;

			qcom,wf-pattern-period-us = <5880>;

			qcom,wf-brake-pattern =
				/bits/ 8 <0x00 0x00 0x00>;

			qcom,wf-auto-res-disable;
		};

		effect_5 {
			qcom,effect-id = <0x05>;

			qcom,wf-vmax-mv = <5000>;

			qcom,wf-pattern-data =
				<0x01f 0x00 0x00
				 0x03f 0x00 0x00
				 0x05f 0x00 0x00
				 0x07f 0x00 0x00
				 0x17f 0x00 0x00
				 0x15f 0x00 0x00
				 0x13f 0x00 0x00
				 0x11f 0x00 0x00>;

			qcom,wf-pattern-period-us = <5880>;

			qcom,wf-brake-pattern =
				/bits/ 8 <0x00 0x00 0x00>;

			qcom,wf-auto-res-disable;
		};
	};
};

&pm8550b_eusb2_repeater {
	qcom,tune-usb2-disc-thres = /bits/ 8 <0x6>;
	qcom,tune-usb2-amplitude = /bits/ 8 <0xd>;
	qcom,tune-usb2-preem = /bits/ 8 <0x7>;
	qcom,squelch-detector-bp = <(-3000)>;
	vdd18-supply = <&vreg_l15b_1p8>;
	vdd3-supply = <&vreg_l5b_3p1>;
};

&pmk8550_gpios {
	/* 【A：RT pmk8550 gpio3 sleep-clk（wcn7850-pmu 消费）】 */
	pmk8550_sleep_clk: sleep-clk-state {
		pins = "gpio3";
		function = "func1";
		input-disable;
		output-enable;
		bias-disable;
		power-source = <0>;
	};
};

&pmk8550_rtc {
	nvmem-cells = <&rtc_offset>;
	nvmem-cell-names = "offset";
};

&pmk8550_sdam_2 {
	rtc_offset: rtc-offset@bc {
		reg = <0xbc 0x4>;
	};
};

&pon_pwrkey {
	status = "okay";
};

&pon_resin {
	linux,code = <KEY_VOLUMEDOWN>;

	status = "okay";
};

&qupv3_id_0 {
	status = "okay";
};

&remoteproc_adsp {
	firmware-name = "qcom/sm8550/meizu/adsp.mbn",
			"qcom/sm8550/meizu/adsp_dtb.mbn";
	status = "okay";
};

/*
 * Stock assigns the ADSP static-PD (audiopd) remote heap to
 * {LPASS, ADSP_HEAP} and hands a dedicated pool to the DSP.  Without
 * memory-region the fastrpc device has no reserved DMA pool (heap born
 * generic) and without vmids qcom_scm_assign_mem() is skipped, so uAPM
 * never starts.  Shape mirrors upstream sm8250/sm8750.
 */
&{/soc@0/remoteproc@6800000/glink-edge/fastrpc} {
	memory-region = <&adsp_rpc_remote_heap_mem>;
	qcom,vmids = <QCOM_SCM_VMID_LPASS QCOM_SCM_VMID_ADSP_HEAP>;
};

&remoteproc_cdsp {
	firmware-name = "qcom/sm8550/meizu/cdsp.mbn",
			"qcom/sm8550/meizu/cdsp_dtb.mbn";
	status = "okay";
};

&remoteproc_mpss {
	firmware-name = "qcom/sm8550/meizu/modem.mbn",
			"qcom/sm8550/meizu/modem_dtb.mbn";
	status = "okay";
};

/* 【A：RT xo_board clock-frequency = 0x493e000 = 76.8MHz】 */
&sleep_clk {
	clock-frequency = <32764>;
};

&swr1 {
	status = "okay";
	wcd_rx: codec@0,4 {
		compatible = "sdw20217010d00";
		reg = <0 4>;
		qcom,rx-port-mapping = <1 2 3 4 5>;
	};
};

&swr2 {
	status = "okay";
	wcd_tx: codec@0,3 {
		compatible = "sdw20217010d00";
		reg = <0 3>;
		qcom,tx-port-mapping = <2 2 3 4>;
	};
};

&tlmm {
	/* 【D：stock 无 gpio-reserved-ranges 声明；<32 8> = QRD 继承观察项，
	 * 台账 D 类（stock TLMM 全开，SPMI 固有保留由 SoC dtsi 管）】 */
	gpio-reserved-ranges = <32 8>;

	i2s1_default: i2s1-default-state {
		sck-pins {
			pins = "gpio121";
			function = "i2s1_sck";
			drive-strength = <8>;
			bias-disable;
		};

		data0-pins {
			pins = "gpio122";
			function = "i2s1_data0";
			drive-strength = <8>;
			bias-disable;
		};

		ws-pins {
			pins = "gpio123";
			function = "i2s1_ws";
			drive-strength = <8>;
			bias-disable;
		};

		data1-pins {
			pins = "gpio124";
			function = "i2s1_data1";
			drive-strength = <8>;
			bias-disable;
		};
	};

	bt_default: bt-default-state {
		bt-en-pins {
			pins = "gpio81";
			function = "gpio";
			drive-strength = <16>;
			bias-disable;
		};

		sw-ctrl-pins {
			pins = "gpio82";
			function = "gpio";
			bias-pull-down;
		};
	};

	ts_irq: ts-irq-state {
		pins = "gpio25";
		function = "gpio";
		drive-strength = <8>;
		bias-pull-up;
	};

	ts_reset: ts-reset-state {
		pins = "gpio24";
		function = "gpio";
		drive-strength = <8>;
		bias-pull-up;
	};

	/* 【A：RT sde_dsi_active/suspend = gpio133 ds8 bias-disable / ds2 pull-down】
	 * 注意：本组与 panel reset-gpios=133 同脚（原厂同形——pinctrl 管态、
	 * 面板驱动管电平翻转）。 */
	sde_dsi_active: sde-dsi-active-state {
		pins = "gpio133";
		function = "gpio";
		drive-strength = <8>;
		bias-disable;
	};

	sde_dsi_suspend: sde-dsi-suspend-state {
		pins = "gpio133";
		function = "gpio";
		drive-strength = <2>;
		bias-pull-down;
	};

	sde_te_active: sde-te-active-state {
		pins = "gpio86";
		function = "mdp_vsync";
		drive-strength = <2>;
		bias-pull-down;
	};

	sde_te_suspend: sde-te-suspend-state {
		pins = "gpio86";
		function = "mdp_vsync";
		drive-strength = <2>;
		bias-pull-down;
	};

	wcd_default: wcd-reset-n-active-state {
		pins = "gpio108";
		function = "gpio";
		drive-strength = <16>;
		bias-disable;
		output-low;
	};

	wlan_en: wlan-en-state {
		pins = "gpio80";
		function = "gpio";
		drive-strength = <8>;
		bias-pull-down;
	};
};

&uart7 {
	status = "okay";
};

&uart14 {
	status = "okay";

	bluetooth {
		compatible = "qcom,wcn7850-bt";

		vddrfacmn-supply = <&vreg_pmu_rfa_cmn>;
		vddaon-supply = <&vreg_pmu_aon_0p59>;
		vddwlcx-supply = <&vreg_pmu_wlcx_0p8>;
		vddwlmx-supply = <&vreg_pmu_wlmx_0p85>;
		vddrfa0p8-supply = <&vreg_pmu_rfa_0p8>;
		vddrfa1p2-supply = <&vreg_pmu_rfa_1p2>;
		vddrfa1p8-supply = <&vreg_pmu_rfa_1p8>;

		max-speed = <3200000>;
		qcom,soc-serial-bd-address;
	};
};

&camss {
	vdda-phy-supply = <&vreg_l1e_0p88>;
	vdda-pll-supply = <&vreg_l3e_1p2>;

	status = "okay";
};

/*
 * Cameras: m2381 四摄全三星（per 本机 dtbo entry9：csiphy/cci 分配见下注），
 * sensor 节点待相机轮（CAMX i2c 地址/上电序在 vendor sensor libs）。
 *   rear  wide   S5KGN5SP03   50MP  csiphy3 cci1 (OIS + AF)
 *   rear  ultra  S5K3P9SX     16MP  csiphy2 cci0 (AF)
 *   rear  depth  S5K5E9YX04    5MP  csiphy1 cci0
 *   front        S5KGD2SP03   32MP  csiphy4 cci1
 * Camera rails = pm8008i/pm8008j LDOs（entry9 侧 pm8008i/j-regulator 在档）。
 */

&ufs_mem_hc {
	/* 【A：RT ufs 节点 reset-gpios = 0xd2 = 210（=硬定律#9 的那根线：UFS 复位，
	 * 勿在他处复用/误标为面板复位）】 */
	reset-gpios = <&tlmm 210 GPIO_ACTIVE_LOW>;
	vcc-supply = <&vreg_l17b_2p5>;
	vcc-max-microamp = <1300000>;
	vccq-supply = <&vreg_l1g_1p2>;
	vccq-max-microamp = <1200000>;
	vdd-hba-supply = <&vreg_l3g_1p2>;

	status = "okay";
};

&ufs_mem_phy {
	vdda-phy-supply = <&vreg_l1d_0p88>;
	vdda-pll-supply = <&vreg_l3e_1p2>;

	status = "okay";
};

&usb_1 {
	/* The PMIC GLINK Type-C connector owns the USB data-role switch. */
	dr_mode = "otg";
	usb-psy-name = "qcom-battmgr-usb";

	status = "okay";
};

&usb_1_dwc3_hs {
	remote-endpoint = <&pmic_glink_hs_in>;
};

&usb_1_hsphy {
	phys = <&pm8550b_eusb2_repeater>;

	vdd-supply = <&vreg_l1e_0p88>;
	vdda12-supply = <&vreg_l3e_1p2>;

	status = "okay";
};

&usb_dp_qmpphy {
	vdda-phy-supply = <&vreg_l3f_0p88>;
	vdda-pll-supply = <&vreg_l3e_1p2>;

	mode-switch;

	status = "okay";
};

&usb_dp_qmpphy_out {
	remote-endpoint = <&redriver_ss_in>;
};

/* 【A：RT xo_board = 76.8MHz；sleep_clk 32.764kHz 主线惯例】 */
&xo_board {
	clock-frequency = <76800000>;
};
